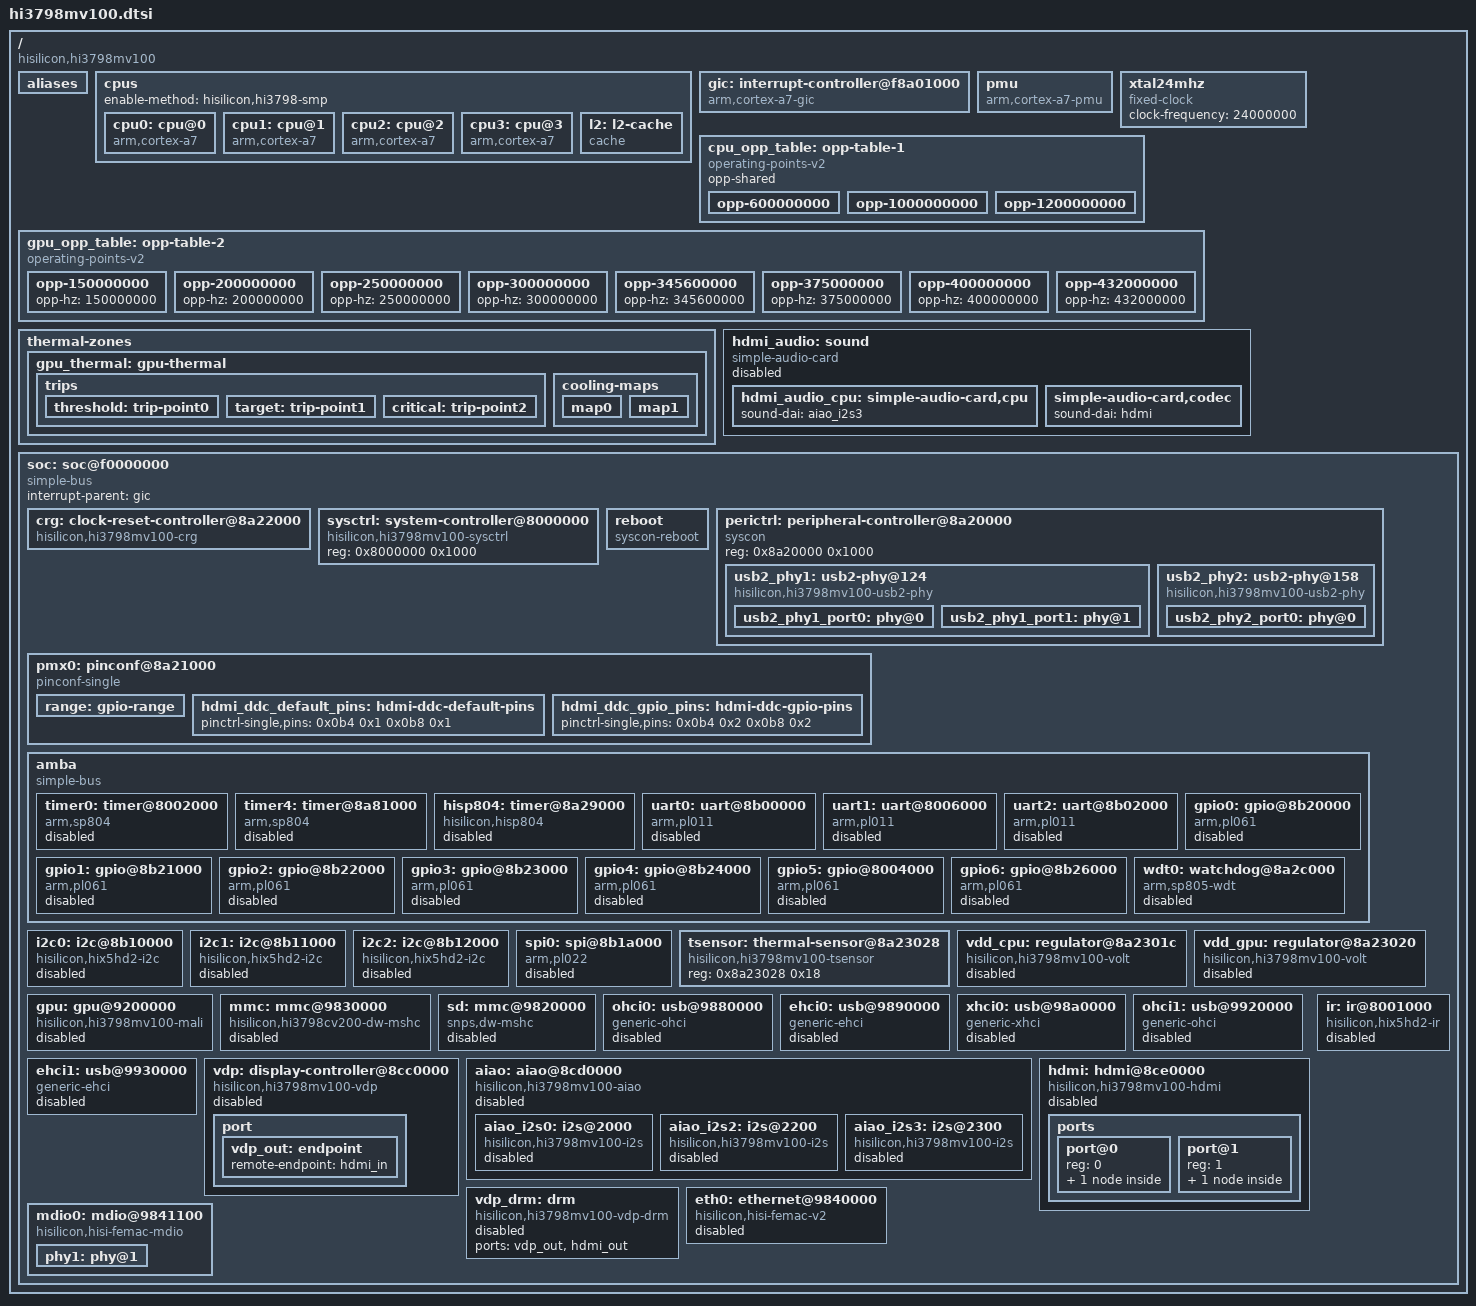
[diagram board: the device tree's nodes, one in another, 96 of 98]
// SPDX-License-Identifier: GPL-2.0
/*
 * Based on arch/arm64/boot/dts/hisilicon/hi3798cv200.dtsi
 *
 * Copyright (c) 2016-2017 HiSilicon Technologies Co., Ltd.
 * Copyright (c) 2023 David Yang
 */

#include <dt-bindings/clock/histb-clock.h>
#include <dt-bindings/gpio/gpio.h>
#include <dt-bindings/interrupt-controller/arm-gic.h>
#include <dt-bindings/phy/phy.h>

/ {
	compatible = "hisilicon,hi3798mv100";
	#address-cells = <1>;
	#size-cells = <1>;

	aliases {
		serial0 = &uart0;
		mmc0 = &mmc;
		mmc1 = &sd;
		sound0 = &hdmi_audio;
	};

	cpus {
		#address-cells = <1>;
		#size-cells = <0>;
		enable-method = "hisilicon,hi3798-smp";

		cpu0: cpu@0 {
			compatible = "arm,cortex-a7";
			device_type = "cpu";
			reg = <0>;
			clock-frequency = <1200000000>;
			clocks = <&crg HISTB_CPU_CLK>;
			operating-points-v2 = <&cpu_opp_table>;
			cpu-supply = <&vdd_cpu>;
			next-level-cache = <&l2>;
		};

		cpu1: cpu@1 {
			compatible = "arm,cortex-a7";
			device_type = "cpu";
			reg = <1>;
			clock-frequency = <1200000000>;
			clocks = <&crg HISTB_CPU_CLK>;
			operating-points-v2 = <&cpu_opp_table>;
			cpu-supply = <&vdd_cpu>;
			next-level-cache = <&l2>;
		};

		cpu2: cpu@2 {
			compatible = "arm,cortex-a7";
			device_type = "cpu";
			reg = <2>;
			clock-frequency = <1200000000>;
			clocks = <&crg HISTB_CPU_CLK>;
			operating-points-v2 = <&cpu_opp_table>;
			cpu-supply = <&vdd_cpu>;
			next-level-cache = <&l2>;
		};

		cpu3: cpu@3 {
			compatible = "arm,cortex-a7";
			device_type = "cpu";
			reg = <3>;
			clock-frequency = <1200000000>;
			clocks = <&crg HISTB_CPU_CLK>;
			operating-points-v2 = <&cpu_opp_table>;
			cpu-supply = <&vdd_cpu>;
			next-level-cache = <&l2>;
		};

		l2: l2-cache {
			compatible = "cache";
			cache-level = <2>;
			cache-unified;
		};
	};

	gic: interrupt-controller@f8a01000 {
		compatible = "arm,cortex-a7-gic";
		#interrupt-cells = <3>;
		#address-cells = <0>;
		interrupt-controller;
		/* gic dist base, gic cpu base */
		reg = <0xf8a01000 0x1000>, <0xf8a02000 0x100>;
	};

	pmu: pmu {
		compatible = "arm,cortex-a7-pmu";
		interrupts = <GIC_SPI 8 IRQ_TYPE_LEVEL_HIGH>,
			<GIC_SPI 9 IRQ_TYPE_LEVEL_HIGH>,
			<GIC_SPI 10 IRQ_TYPE_LEVEL_HIGH>,
			<GIC_SPI 11 IRQ_TYPE_LEVEL_HIGH>;
		interrupt-affinity = <&cpu0>, <&cpu1>, <&cpu2>, <&cpu3>;
		interrupt-parent = <&gic>;
	};

	xtal24mhz: xtal24mhz {
		compatible = "fixed-clock";
		#clock-cells = <0>;
		clock-frequency = <24000000>;
	};

		cpu_opp_table: opp-table-1 {
			compatible = "operating-points-v2";
			opp-shared;

			opp-600000000 {
				opp-hz = /bits/ 64 <600000000>;
				opp-microvolt = <1150000>;
				clock-latency-ns = <10000000>;
			};
			opp-1000000000 {
				opp-hz = /bits/ 64 <1000000000>;
				opp-microvolt = <1300000>;
				clock-latency-ns = <10000000>;
			};
			opp-1200000000 {
				opp-hz = /bits/ 64 <1200000000>;
				opp-microvolt = <1420000>;
				clock-latency-ns = <10000000>;
			};
		};

	gpu_opp_table: opp-table-2 {
		compatible = "operating-points-v2";

		opp-150000000 {
			opp-hz = /bits/ 64 <150000000>;
		};
		opp-200000000 {
			opp-hz = /bits/ 64 <200000000>;
		};
		opp-250000000 {
			opp-hz = /bits/ 64 <250000000>;
		};
		opp-300000000 {
			opp-hz = /bits/ 64 <300000000>;
		};
		opp-345600000 {
			opp-hz = /bits/ 64 <345600000>;
		};
		opp-375000000 {
			opp-hz = /bits/ 64 <375000000>;
		};
		opp-400000000 {
			opp-hz = /bits/ 64 <400000000>;
		};
		opp-432000000 {
			opp-hz = /bits/ 64 <432000000>;
		};
	};

			thermal-zones {
				gpu_thermal: gpu-thermal {
					polling-delay = <1000>;
					polling-delay-passive = <100>;
					sustainable-power = <2500>;

					thermal-sensors = <&tsensor 0>;

					trips {
						threshold: trip-point0 {
							temperature = <95000>;
							hysteresis = <5000>;
							type = "passive";
						};

						target: trip-point1 {
							temperature = <105000>;
							hysteresis = <5000>;
							type = "passive";
						};

						critical: trip-point2 {
							temperature = <120000>;
							hysteresis = <5000>;
							type = "critical";
						};
					};

					cooling-maps {
						map0 {
							trip = <&threshold>;
							cooling-device = <&gpu 0 3>;
							contribution = <512>;
						};
						map1 {
							trip = <&target>;
							cooling-device = <&gpu 0 7>;
							contribution = <1024>;
						};
					};
				};
			};

			/* Audio routing: aiao_i2s3 -> hdmi_audio -> hdmi */
			hdmi_audio: sound {
				compatible = "simple-audio-card";
				simple-audio-card,name = "hi3798mv100-hdmi";
				simple-audio-card,format = "i2s";
				simple-audio-card,mclk-fs = <256>;
				simple-audio-card,bitclock-master = <&hdmi_audio_cpu>;
				simple-audio-card,frame-master = <&hdmi_audio_cpu>;
				status = "disabled";

				hdmi_audio_cpu: simple-audio-card,cpu {
					sound-dai = <&aiao_i2s3>;
				};

				simple-audio-card,codec {
					sound-dai = <&hdmi>;
				};
			};

			soc: soc@f0000000 {
			compatible = "simple-bus";
		#address-cells = <1>;
		#size-cells = <1>;
		interrupt-parent = <&gic>;
		ranges = <0 0xf0000000 0x10000000>;

			crg: clock-reset-controller@8a22000 {
				compatible = "hisilicon,hi3798mv100-crg", "hisilicon,cpuctrl", "syscon", "simple-mfd";
				reg = <0x8a22000 0x2000>;
				hisilicon,sysctrl = <&sysctrl>;
				hisilicon,perictrl = <&perictrl>;
				#clock-cells = <1>;
				#reset-cells = <2>;
			};

		sysctrl: system-controller@8000000 {
			compatible = "hisilicon,hi3798mv100-sysctrl", "syscon";
			reg = <0x8000000 0x1000>;
			#clock-cells = <1>;
			#reset-cells = <2>;
		};

		reboot {
			compatible = "syscon-reboot";
			regmap = <&sysctrl>;
			/* SC_SYSRES: bit 0 resets the whole chipset. */
			offset = <0x4>;
			value = <0x1>;
			mask = <0x1>;
		};

		perictrl: peripheral-controller@8a20000 {
			compatible = "syscon", "simple-mfd";
			reg = <0x8a20000 0x1000>;
			#address-cells = <1>;
			#size-cells = <1>;
			ranges = <0x0 0x8a20000 0x1000>;

			usb2_phy1: usb2-phy@124 {
				compatible = "hisilicon,hi3798mv100-usb2-phy";
				reg = <0x124 0x4>;
				clocks = <&crg HISTB_USB2_PHY1_REF_CLK>;
				resets = <&crg 0xbc 8>;
				status = "okay";

				#address-cells = <1>;
				#size-cells = <0>;

				usb2_phy1_port0: phy@0 {
					reg = <0>;
					#phy-cells = <0>;
					resets = <&crg 0xbc 9>;
				};

				usb2_phy1_port1: phy@1 {
					reg = <1>;
					#phy-cells = <0>;
					resets = <&crg 0xbc 11>;
				};
			};

			usb2_phy2: usb2-phy@158 {
				compatible = "hisilicon,hi3798mv100-usb2-phy";
				reg = <0x158 0x4>;
				clocks = <&crg HISTB_USB2_2_PHY1_REF_CLK>;
				resets = <&crg 0x190 8>;
				status = "okay";

				#address-cells = <1>;
				#size-cells = <0>;

				usb2_phy2_port0: phy@0 {
					reg = <0>;
					#phy-cells = <0>;
					resets = <&crg 0x190 9>;
				};
			};
		};

		pmx0: pinconf@8a21000 {
			compatible = "pinconf-single";
			reg = <0x8a21000 0x180>;
			#pinctrl-cells = <1>;
			pinctrl-single,register-width = <32>;
			pinctrl-single,function-mask = <7>;
			pinctrl-single,gpio-range = <&range 8 3 2>, <&range 79 1 0>, <&range 21 4 5>,
								<&range 25 1 5>, <&range 54 1 2>, <&range 55 2 0>,
								<&range 78 1 1>, <&range 31 1 6>, <&range 32 1 1>,
								<&range 57 8 0>, <&range 80 2 0>, <&range 43 1 2>,
								<&range 44 1 0>, <&range 45 4 2>, <&range 82 8 0>;

			range: gpio-range {
				#pinctrl-single,gpio-range-cells = <3>;
			};

			hdmi_ddc_default_pins: hdmi-ddc-default-pins {
				pinctrl-single,pins = <
					0x0b4 0x1 /* ioshare_45: HDMI_TX_SDA */
					0x0b8 0x1 /* ioshare_46: HDMI_TX_SCL */
				>;
			};

			hdmi_ddc_gpio_pins: hdmi-ddc-gpio-pins {
				pinctrl-single,pins = <
					0x0b4 0x2 /* GPIO4_4 for DDC recovery */
					0x0b8 0x2 /* GPIO4_5 for DDC recovery */
				>;
			};
		};

		amba {
			#address-cells = <1>;
			#size-cells = <1>;
			compatible = "simple-bus";
			ranges;

			timer0: timer@8002000 {
				/* MCU only. Unavailable for user. */
				compatible = "arm,sp804", "arm,primecell";
				reg = <0x8002000 0x1000>;
				/* timer00 & timer01 */
				interrupts = <GIC_SPI 24 IRQ_TYPE_LEVEL_HIGH>;
				clocks = <&xtal24mhz>;
				clock-names = "apb_pclk";
				status = "disabled";
			};

			timer4: timer@8a81000 {
				compatible = "arm,sp804", "arm,primecell";
				reg = <0x8a81000 0x1000>;
				/* timer40 & timer41 */
				interrupts = <GIC_SPI 28 IRQ_TYPE_LEVEL_HIGH>;
				clocks = <&xtal24mhz>;
				clock-names = "apb_pclk";
				status = "disabled";
			};

			/*
			 * Timers 1..3 of the SP804 block, driven as one
			 * clocksource plus a per-CPU clockevent. Only usable
			 * in NORMAL state (not SLOW/DOZE), the rate is fixed
			 * at 24MHz.
			 */
			hisp804: timer@8a29000 {
				compatible = "hisilicon,hisp804";
				reg = <0x8a29000 0x20>, /* clocksource */
				      <0x8a2a000 0x20>, /* local timer for cpu0 */
				      <0x8a2a020 0x20>, /* local timer for cpu1 */
				      <0x8a2b000 0x20>, /* local timer for cpu2 */
				      <0x8a2b020 0x20>; /* local timer for cpu3 */
				interrupts = <GIC_SPI 26 IRQ_TYPE_LEVEL_HIGH>,
					     <GIC_SPI 59 IRQ_TYPE_LEVEL_HIGH>,
					     <GIC_SPI 27 IRQ_TYPE_LEVEL_HIGH>,
					     <GIC_SPI 60 IRQ_TYPE_LEVEL_HIGH>;
				clocks = <&xtal24mhz>;
				clock-names = "apb_pclk";
				status = "disabled";
			};

			uart0: uart@8b00000 {
				compatible = "arm,pl011", "arm,primecell";
				reg = <0x8b00000 0x1000>;
				interrupts = <GIC_SPI 49 IRQ_TYPE_LEVEL_HIGH>;
				clocks = <&sysctrl HISTB_UART0_CLK>, <&sysctrl HISTB_UART0_CLK>;
				clock-names = "uartclk", "apb_pclk";
				resets = <&sysctrl 0x48 13>;
				reset-names = "reset";
				status = "disabled";
			};

			uart1: uart@8006000 {
				compatible = "arm,pl011", "arm,primecell";
				reg = <0x8006000 0x1000>;
				interrupts = <GIC_SPI 50 IRQ_TYPE_LEVEL_HIGH>;
				clocks = <&crg HISTB_UART1_CLK>, <&crg HISTB_UART1_CLK>;
				clock-names = "uartclk", "apb_pclk";
				resets = <&crg 0x68 1>;
				reset-names = "reset";
				status = "disabled";
			};

			uart2: uart@8b02000 {
				compatible = "arm,pl011", "arm,primecell";
				reg = <0x8b02000 0x1000>;
				interrupts = <GIC_SPI 51 IRQ_TYPE_LEVEL_HIGH>;
				clocks = <&crg HISTB_UART2_CLK>, <&crg HISTB_UART2_CLK>;
				clock-names = "uartclk", "apb_pclk";
				resets = <&crg 0x68 5>;
				reset-names = "reset";
				status = "disabled";
			};

			gpio0: gpio@8b20000 {
				compatible = "arm,pl061", "arm,primecell";
				reg = <0x8b20000 0x1000>;
				interrupts = <GIC_SPI 108 IRQ_TYPE_LEVEL_HIGH>;
				gpio-controller;
				#gpio-cells = <2>;
				ngpios = <8>;
				interrupt-controller;
				#interrupt-cells = <2>;
				clocks = <&crg HISTB_APB_CLK>;
				clock-names = "apb_pclk";
				status = "disabled";
				gpio-line-names = "GPIO0_0", "GPIO0_1", "GPIO0_2", "GPIO0_3", "GPIO0_4", "GPIO0_5", "GPIO0_6", "GPIO0_7";
				gpio-ranges = <&pmx0 2 10 1>, <&pmx0 3 79 1>, <&pmx0 4 21 4>;
			};

			gpio1: gpio@8b21000 {
				compatible = "arm,pl061", "arm,primecell";
				reg = <0x8b21000 0x1000>;
				interrupts = <GIC_SPI 109 IRQ_TYPE_LEVEL_HIGH>;
				gpio-controller;
				#gpio-cells = <2>;
				ngpios = <8>;
				interrupt-controller;
				#interrupt-cells = <2>;
				clocks = <&crg HISTB_APB_CLK>;
				clock-names = "apb_pclk";
				status = "disabled";
				gpio-line-names = "GPIO1_0", "GPIO1_1", "GPIO1_2", "GPIO1_3", "GPIO1_4", "GPIO1_5", "GPIO1_6", "GPIO1_7";
			};

			gpio2: gpio@8b22000 {
				compatible = "arm,pl061", "arm,primecell";
				reg = <0x8b22000 0x1000>;
				interrupts = <GIC_SPI 110 IRQ_TYPE_LEVEL_HIGH>;
				gpio-controller;
				#gpio-cells = <2>;
				ngpios = <8>;
				interrupt-controller;
				#interrupt-cells = <2>;
				clocks = <&crg HISTB_APB_CLK>;
				clock-names = "apb_pclk";
				status = "disabled";
				gpio-line-names = "GPIO2_0", "GPIO2_1", "GPIO2_2", "GPIO2_3", "GPIO2_4", "GPIO2_5", "GPIO2_6", "GPIO2_7";
				gpio-ranges = <&pmx0 0 25 1>, <&pmx0 1 54 1>, <&pmx0 2 55 2>;
			};

			gpio3: gpio@8b23000 {
				compatible = "arm,pl061", "arm,primecell";
				reg = <0x8b23000 0x1000>;
				interrupts = <GIC_SPI 111 IRQ_TYPE_LEVEL_HIGH>;
				gpio-controller;
				#gpio-cells = <2>;
				ngpios = <8>;
				interrupt-controller;
				#interrupt-cells = <2>;
				clocks = <&crg HISTB_APB_CLK>;
				clock-names = "apb_pclk";
				status = "disabled";
				gpio-line-names = "GPIO3_0", "GPIO3_1", "GPIO3_2", "GPIO3_3", "GPIO3_4", "GPIO3_5", "GPIO3_6", "GPIO3_7";
			};

			gpio4: gpio@8b24000 {
				compatible = "arm,pl061", "arm,primecell";
				reg = <0x8b24000 0x1000>;
				interrupts = <GIC_SPI 112 IRQ_TYPE_LEVEL_HIGH>;
				gpio-controller;
				#gpio-cells = <2>;
				ngpios = <8>;
				interrupt-controller;
				#interrupt-cells = <2>;
				clocks = <&crg HISTB_APB_CLK>;
				clock-names = "apb_pclk";
				status = "disabled";
				gpio-line-names = "GPIO4_0", "GPIO4_1", "GPIO4_2", "GPIO4_3", "GPIO4_4", "GPIO4_5", "GPIO4_6", "GPIO4_7";
				gpio-ranges = <&pmx0 0 80 2>, <&pmx0 2 43 2>, <&pmx0 4 45 4>;
			};

			gpio5: gpio@8004000 {
				compatible = "arm,pl061", "arm,primecell";
				reg = <0x8004000 0x1000>;
				interrupts = <GIC_SPI 113 IRQ_TYPE_LEVEL_HIGH>;
				gpio-controller;
				#gpio-cells = <2>;
				ngpios = <8>;
				interrupt-controller;
				#interrupt-cells = <2>;
				clocks = <&crg HISTB_APB_CLK>;
				clock-names = "apb_pclk";
				status = "disabled";
				gpio-line-names = "GPIO5_0", "GPIO5_1", "GPIO5_2", "GPIO5_3", "GPIO5_4", "GPIO5_5", "GPIO5_6", "GPIO5_7";
			};

			gpio6: gpio@8b26000 {
				compatible = "arm,pl061", "arm,primecell";
				reg = <0x8b26000 0x1000>;
				interrupts = <GIC_SPI 114 IRQ_TYPE_LEVEL_HIGH>;
				gpio-controller;
				#gpio-cells = <2>;
				ngpios = <8>;
				interrupt-controller;
				#interrupt-cells = <2>;
				clocks = <&crg HISTB_APB_CLK>;
				clock-names = "apb_pclk";
				status = "disabled";
				gpio-line-names = "GPIO6_0", "GPIO6_1", "GPIO6_2", "GPIO6_3", "GPIO6_4", "GPIO6_5", "GPIO6_6", "GPIO6_7";
				gpio-ranges = <&pmx0 0 82 2>;
			};

			wdt0: watchdog@8a2c000 {
				compatible = "arm,sp805-wdt", "arm,primecell";
				arm,primecell-periphid = <0x00141805>;
				reg = <0x8a2c000 0x1000>;
				interrupts = <GIC_SPI 29 IRQ_TYPE_LEVEL_HIGH>;
				clocks = <&crg HISTB_APB_CLK>;
				clock-names = "apb_pclk";
				status = "disabled";
			};
		};

		i2c0: i2c@8b10000 {
			compatible = "hisilicon,hix5hd2-i2c";
			reg = <0x8b10000 0x1000>;
			interrupts = <GIC_SPI 38 IRQ_TYPE_LEVEL_HIGH>;
			clock-frequency = <400000>;
			clocks = <&crg HISTB_I2C0_CLK>;
			resets = <&crg 0x6c 5>;
			reset-names = "reset";
			status = "disabled";
		};

		i2c1: i2c@8b11000 {
			compatible = "hisilicon,hix5hd2-i2c";
			reg = <0x8b11000 0x1000>;
			interrupts = <GIC_SPI 39 IRQ_TYPE_LEVEL_HIGH>;
			clock-frequency = <400000>;
			clocks = <&crg HISTB_I2C1_CLK>;
			resets = <&crg 0x6c 9>;
			reset-names = "reset";
			status = "disabled";
		};

		i2c2: i2c@8b12000 {
			compatible = "hisilicon,hix5hd2-i2c";
			reg = <0x8b12000 0x1000>;
			interrupts = <GIC_SPI 40 IRQ_TYPE_LEVEL_HIGH>;
			clock-frequency = <400000>;
			clocks = <&crg HISTB_I2C2_CLK>;
			resets = <&crg 0x6c 13>;
			reset-names = "reset";
			status = "disabled";
		};

			spi0: spi@8b1a000 {
				compatible = "arm,pl022", "arm,primecell";
				reg = <0x8b1a000 0x1000>;
			interrupts = <GIC_SPI 45 IRQ_TYPE_LEVEL_HIGH>;
			num-cs = <1>;
			clocks = <&crg HISTB_SPI0_CLK>, <&crg HISTB_SPI0_CLK>;
			clock-names = "sspclk", "apb_pclk";
			resets = <&crg 0x70 1>;
			reset-names = "reset";
				status = "disabled";
			};

			tsensor: thermal-sensor@8a23028 {
				compatible = "hisilicon,hi3798mv100-tsensor";
				reg = <0x8a23028 0x18>;
				#thermal-sensor-cells = <1>;
			};

			vdd_cpu: regulator@8a2301c {
				compatible = "hisilicon,hi3798mv100-volt";
				reg = <0x8a2301c 0x4>;
				reg-names = "base-address";
				regulator-name = "vdd-cpu";
				regulator-min-microvolt = <920000>;
				regulator-max-microvolt = <1495000>;
				regulator-settling-time-up-us = <10000>;
				regulator-settling-time-down-us = <10000>;
				regulator-boot-on;
				regulator-always-on;
				status = "disabled";
			};

			vdd_gpu: regulator@8a23020 {
				compatible = "hisilicon,hi3798mv100-volt";
				reg = <0x8a23020 0x4>;
				reg-names = "base-address";
				regulator-name = "vdd-gpu";
				regulator-min-microvolt = <900000>;
				regulator-max-microvolt = <1320000>;
				regulator-settling-time-us = <1000>;
				regulator-boot-on;
				regulator-always-on;
				status = "disabled";
			};

		gpu: gpu@9200000 {
			compatible = "hisilicon,hi3798mv100-mali", "arm,mali-450";
			reg = <0x9200000 0x30000>;
			interrupts = <GIC_SPI 94 IRQ_TYPE_LEVEL_HIGH>,
				     <GIC_SPI 94 IRQ_TYPE_LEVEL_HIGH>,
				     <GIC_SPI 94 IRQ_TYPE_LEVEL_HIGH>,
				     <GIC_SPI 94 IRQ_TYPE_LEVEL_HIGH>,
				     <GIC_SPI 94 IRQ_TYPE_LEVEL_HIGH>,
				     <GIC_SPI 94 IRQ_TYPE_LEVEL_HIGH>,
				     <GIC_SPI 94 IRQ_TYPE_LEVEL_HIGH>,
				     <GIC_SPI 94 IRQ_TYPE_LEVEL_HIGH>;
			interrupt-names = "gp", "gpmmu", "pp0", "ppmmu0", "pp1",
					  "ppmmu1", "pmu", "pp";

			clocks = <&crg HISTB_GPU_BUS_CLK>, <&crg HISTB_GPU_GP_CLK>;
			clock-names = "bus", "core";
			resets = <&crg 0xd4 4>;
			status = "disabled";

			operating-points-v2 = <&gpu_opp_table>;
			#cooling-cells = <2>; /* min followed by max */
		};

		/* unremovable emmc as mmcblk0 */
		mmc: mmc@9830000 {
			compatible = "hisilicon,hi3798cv200-dw-mshc";
			reg = <0x9830000 0x10000>;
			interrupts = <GIC_SPI 35 IRQ_TYPE_LEVEL_HIGH>;
			clocks = <&crg HISTB_MMC_CIU_CLK>,
				 <&crg HISTB_MMC_BIU_CLK>,
				 <&crg HISTB_MMC_SAMPLE_CLK>,
				 <&crg HISTB_MMC_DRV_CLK>;
			clock-names = "ciu", "biu", "ciu-sample", "ciu-drive";
			resets = <&crg 0xa0 4>;
			reset-names = "reset";
			status = "disabled";
		};

		sd: mmc@9820000 {
			compatible = "snps,dw-mshc";
			reg = <0x9820000 0x10000>;
			interrupts = <GIC_SPI 34 IRQ_TYPE_LEVEL_HIGH>;
			clocks = <&crg HISTB_SDIO0_CIU_CLK>,
				 <&crg HISTB_SDIO0_BIU_CLK>;
			clock-names = "ciu", "biu";
			resets = <&crg 0x9c 4>;
			reset-names = "reset";
			status = "disabled";
		};

		ohci0: usb@9880000 {
			compatible = "generic-ohci";
			reg = <0x9880000 0x10000>;
			interrupts = <GIC_SPI 67 IRQ_TYPE_LEVEL_HIGH>;
			clocks = <&crg HISTB_USB2_BUS_CLK>,
				 <&crg HISTB_USB2_12M_CLK>,
				 <&crg HISTB_USB2_48M_CLK>;
			clock-names = "bus", "clk12", "clk48";
			resets = <&crg 0xb8 12>;
			reset-names = "bus";
			phys = <&usb2_phy1_port0>, <&usb2_phy1_port1>;
			phy-names = "usb0", "usb1";
			status = "disabled";
		};

		ehci0: usb@9890000 {
			compatible = "generic-ehci";
			reg = <0x9890000 0x10000>;
			interrupts = <GIC_SPI 66 IRQ_TYPE_LEVEL_HIGH>;
			clocks = <&crg HISTB_USB2_BUS_CLK>,
				 <&crg HISTB_USB2_PHY_CLK>,
				 <&crg HISTB_USB2_UTMI_CLK>,
				 <&crg HISTB_USB2_UTMI_CLK1>;
			clock-names = "bus", "phy", "utmi0", "utmi1";
			resets = <&crg 0xb8 12>,
				 <&crg 0xb8 16>,
				 <&crg 0xb8 13>,
				 <&crg 0xb8 14>;
			reset-names = "bus", "phy", "utmi0", "utmi1";
			phys = <&usb2_phy1_port0>, <&usb2_phy1_port1>;
			phy-names = "usb0", "usb1";
			status = "disabled";
		};

		xhci0: usb@98a0000 {
			compatible = "generic-xhci";
			reg = <0x98a0000 0x10000>;
			interrupts = <GIC_SPI 69 IRQ_TYPE_LEVEL_HIGH>;
			clocks = <&crg HISTB_USB3_BUS_CLK>,
				 <&crg HISTB_USB3_UTMI_CLK>,
				 <&crg HISTB_USB3_PIPE_CLK>,
				 <&crg HISTB_USB3_SUSPEND_CLK>;
			clock-names = "bus", "utmi0", "pipe", "suspend";
			resets = <&crg 0xb0 12>;
			reset-names = "vcc";
			status = "disabled";
		};

		ohci1: usb@9920000 {
			compatible = "generic-ohci";
			reg = <0x9920000 0x10000>;
			interrupts = <GIC_SPI 63 IRQ_TYPE_LEVEL_HIGH>;
			clocks = <&crg HISTB_USB2_2_BUS_CLK>,
				 <&crg HISTB_USB2_2_12M_CLK>,
				 <&crg HISTB_USB2_2_48M_CLK>;
			clock-names = "bus", "clk12", "clk48";
			resets = <&crg 0x198 12>;
			reset-names = "bus";
			phys = <&usb2_phy2_port0>;
			phy-names = "usb";
			status = "disabled";
		};

			ehci1: usb@9930000 {
				compatible = "generic-ehci";
				reg = <0x9930000 0x10000>;
			interrupts = <GIC_SPI 62 IRQ_TYPE_LEVEL_HIGH>;
			clocks = <&crg HISTB_USB2_2_BUS_CLK>,
				 <&crg HISTB_USB2_2_PHY_CLK>,
				 <&crg HISTB_USB2_2_UTMI_CLK>;
			clock-names = "bus", "phy", "utmi";
			resets = <&crg 0x198 12>,
				 <&crg 0x198 16>,
				 <&crg 0x198 14>;
			reset-names = "bus", "phy", "utmi";
			phys = <&usb2_phy2_port0>;
			phy-names = "usb";
				status = "disabled";
			};

				vdp: display-controller@8cc0000 {
					compatible = "hisilicon,hi3798mv100-vdp";
					reg = <0x8cc0000 0x10000>;
					interrupts = <GIC_SPI 90 IRQ_TYPE_LEVEL_HIGH>;
					clocks = <&crg HISTB_VO_BUS_CLK>,
						 <&crg HISTB_VO_CLK>,
						 <&crg HISTB_VO_SD_CLK>,
						 <&crg HISTB_VO_SDATE_CLK>,
						 <&crg HISTB_VO_HD_CLK>,
						 <&crg HISTB_VO_HDATE_CLK>;
					clock-names = "bus", "vo", "sd", "sdate", "hd", "hdate";
					resets = <&crg 0xd8 30>;
					reset-names = "vou";
					hisilicon,crg-syscon = <&crg>;
					status = "disabled";

					port {
						vdp_out: endpoint {
							remote-endpoint = <&hdmi_in>;
						};
					};
				};

					aiao: aiao@8cd0000 {
						compatible = "hisilicon,hi3798mv100-aiao",
							     "simple-bus";
						reg = <0x8cd0000 0x10000>;
						interrupts = <GIC_SPI 84 IRQ_TYPE_LEVEL_HIGH>;
						clocks = <&crg HISTB_AIAO_CLK>;
						clock-names = "aiao";
						resets = <&crg 0x118 4>;
						reset-names = "core";
					#address-cells = <1>;
					#size-cells = <1>;
					ranges = <0x0 0x8cd0000 0x10000>;
					status = "disabled";

						aiao_i2s0: i2s@2000 {
							compatible = "hisilicon,hi3798mv100-i2s";
							reg = <0x2000 0x100>;
							interrupts = <GIC_SPI 84 IRQ_TYPE_LEVEL_HIGH>;
							clocks = <&crg HISTB_AIAO_CLK>;
							clock-names = "mclk";
							resets = <&crg 0x118 4>;
							reset-names = "core";
							#sound-dai-cells = <0>;
							status = "disabled";
						};

						aiao_i2s2: i2s@2200 {
							compatible = "hisilicon,hi3798mv100-i2s";
							reg = <0x2200 0x100>;
							interrupts = <GIC_SPI 84 IRQ_TYPE_LEVEL_HIGH>;
							clocks = <&crg HISTB_AIAO_CLK>;
							clock-names = "mclk";
							resets = <&crg 0x118 4>;
							reset-names = "core";
							#sound-dai-cells = <0>;
							status = "disabled";
						};

						aiao_i2s3: i2s@2300 {
							compatible = "hisilicon,hi3798mv100-i2s";
							reg = <0x2300 0x100>;
							interrupts = <GIC_SPI 84 IRQ_TYPE_LEVEL_HIGH>;
							clocks = <&crg HISTB_AIAO_CLK>;
							clock-names = "mclk";
							resets = <&crg 0x118 4>;
							reset-names = "core";
							#sound-dai-cells = <0>;
							status = "disabled";
						};
				};

				hdmi: hdmi@8ce0000 {
					compatible = "hisilicon,hi3798mv100-hdmi";
					reg = <0x8ce0000 0x20000>;
					interrupts = <GIC_SPI 88 IRQ_TYPE_LEVEL_HIGH>;
					clocks = <&crg HISTB_HDMI_TX_BUS_CLK>,
						 <&crg HISTB_HDMI_TX_CEC_CLK>,
						 <&crg HISTB_HDMI_TX_ID_CLK>,
						 <&crg HISTB_HDMI_TX_MHL_CLK>,
						 <&crg HISTB_HDMI_TX_OS_CLK>,
						 <&crg HISTB_HDMI_TX_AS_CLK>,
						 <&crg HISTB_HDMI_PHY_BUS_CLK>;
					clock-names = "bus", "cec", "id", "mhl", "os", "as",
						      "phy_bus";
					resets = <&crg 0x10c 8>,
						 <&crg 0x10c 9>,
						 <&crg 0x110 4>;
					reset-names = "bus", "ctrl", "phy";
					#sound-dai-cells = <0>;
					hisilicon,crg-syscon = <&crg>;
					hisilicon,peripheral-syscon = <&perictrl>;
					pinctrl-names = "default", "gpio";
					pinctrl-0 = <&hdmi_ddc_default_pins>;
					pinctrl-1 = <&hdmi_ddc_gpio_pins>;
					status = "disabled";

					ports {
						#address-cells = <1>;
						#size-cells = <0>;

						port@0 {
							reg = <0>;

							hdmi_in: endpoint {
								remote-endpoint = <&vdp_out>;
							};
						};

						port@1 {
							reg = <1>;

							hdmi_out: endpoint {
							};
						};
					};
				};

			vdp_drm: drm {
				compatible = "hisilicon,hi3798mv100-vdp-drm";
				ports = <&vdp_out>, <&hdmi_out>;
				status = "disabled";
			};

		eth0: ethernet@9840000 {
			compatible = "hisilicon,hisi-femac-v2";
			reg = <0x9840000 0x1000>, <0x9841300 0x200>;
			interrupts = <GIC_SPI 71 IRQ_TYPE_LEVEL_HIGH>;
			clocks = <&crg HISTB_ETH0_MAC_CLK>;
			resets = <&crg 0xcc 4>, <&crg 0x120 4>;
			reset-names = "mac", "phy";
			status = "disabled";

			phy-handle = <&phy1>;
			phy-mode = "mii";
			hisilicon,phy-reset-delays-us = <10000 10000 20000>;
		};

		mdio0: mdio@9841100 {
			compatible = "hisilicon,hisi-femac-mdio";
			reg = <0x9841100 0x10>;
			clocks = <&crg HISTB_FEPHY_CLK>;

			#address-cells = <1>;
			#size-cells = <0>;

			phy1: phy@1 {
				reg = <1>;
				/* Placeholder, overwritten by bootloader */
				mac-address = [00 00 00 00 00 00];
			};
		};

		ir: ir@8001000 {
			compatible = "hisilicon,hix5hd2-ir";
			reg = <0x8001000 0x1000>;
			interrupts = <GIC_SPI 47 IRQ_TYPE_LEVEL_HIGH>;
			clocks = <&sysctrl HISTB_IR_CLK>;
			clock-names = "apb_pclk";
			resets = <&sysctrl 0x48 5>;
			reset-names = "reset";
			status = "disabled";
		};
	};
};
